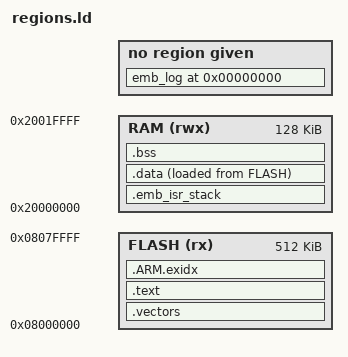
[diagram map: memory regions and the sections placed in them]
/* SPDX-License-Identifier: Apache-2.0 */
/*
 * This file is part of EmbLinkRTOS, a deterministic real-time kernel for microcontrollers.
 * Licensed under the Apache License, Version 2.0; see the LICENSE file at the repository root.
 */

/**
 * @file    regions.ld
 * @brief   Linker script for nucleo_f446ze (STM32F446ZE): the app partition in FLASH, RAM from
 *          sram1 + sram2. The kernel's registration tables are bracketed by name (SPEC-001 §6.4,
 *          HW-006).
 *
 * @details
 * Generated by emb-hwgen 0.1.0, schema v0. Do not edit: change the
 * description and run
 *   hw/gen/emb-hwgen.py generate --system examples/controller/system.yaml
 * (HW-003).
 * Inputs (SHA-256):
 *   arch/cortex_m/arch.yaml
 *     c5c8e451c09717dee1713d07f8311b6d507e3b4c66c42d93e0ce11da6ec76d6d
 *   boards/st/nucleo_f446ze/board.yaml
 *     1525ea206692663af174039e30776d6a9a9b30275c9e5c9bdabf14ac0b70aa19
 *   drivers/bindings.yaml
 *     8ebddec3b88fbfaa96769bf53f915ef6e916352d5abf4b9f676210fcb918d2c9
 *   examples/controller/controller.conf
 *     f7354e5137f5ea50fbd1d5829ff4f5eb88a044100d871d6a8fd7d976339a75f1
 *   examples/controller/system.yaml
 *     2a91f71f1de638aa1ffaa18f0f76fc3ccde44d2560aef98a9a48120775773af3
 *   soc/st/stm32f4/stm32f4.yaml
 *     796886c294250aa81151a620d80d0e43b5ee8e1bf53a07d1d7e2c62e95214dbd
 *   soc/st/stm32f4/stm32f446.yaml
 *     bc475c4bf8703f3bc028f963f6ddf5f1ca508dc726629ea28cca8b38679318f9
 *   soc/st/stm32f4/stm32f446ze.yaml
 *     dabae95e9e4bc984c1a33275966665e0252068e929fe3b430d06589da6bdb6c9
 */
ENTRY(embn_cm_reset)

MEMORY
{
  FLASH (rx)  : ORIGIN = 0x08000000, LENGTH = 512K
  RAM   (rwx) : ORIGIN = 0x20000000, LENGTH = 128K
}

SECTIONS
{
  /* the vector table, then any block the SoC's boot ROM looks for near the image's start
     (the RP2350's IMAGE_DEF, A79) */
  .vectors : { KEEP(*(.vectors)) KEEP(*(.emb_boot_block)) } > FLASH

  .text : {
    *(.text .text.*)
    *(.rodata .rodata.*)
    . = ALIGN(16); /* the table entries' own alignment (sizeof(void *) * 4) */
    __start_emb_init_table = .;
    KEEP(*(emb_init_table))
    __stop_emb_init_table = .;
    . = ALIGN(16);
    __start_emb_test_table = .;
    KEEP(*(emb_test_table))
    __stop_emb_test_table = .;
    . = ALIGN(8);
  } > FLASH

  .ARM.exidx : { *(.ARM.exidx* .gnu.linkonce.armexidx.*) } > FLASH

  /* the interrupt stack, MSP (CONFIG_EMB_ISR_STACK_SIZE, A90): first in RAM, so that an
     overflow runs off the bottom of RAM into a bus fault, not into .data */
  .emb_isr_stack (NOLOAD) : ALIGN(8) {
    __emb_isr_stack_start = .;
    KEEP(*(.emb_isr_stack))
    __emb_isr_stack_end = .;
  } > RAM

  __data_load = LOADADDR(.data);
  .data : ALIGN(8) {
    __data_start = .;
    /* code that runs from RAM, copied with the data: the RP2350's flash routines, which run
       while XIP is off (SPEC-017 §9) */
    *(.ramfunc .ramfunc.*)
    *(.data .data.*)
    . = ALIGN(8);
    __data_end = .;
  } > RAM AT > FLASH

  .bss (NOLOAD) : ALIGN(8) {
    __bss_start = .;
    *(.bss .bss.* COMMON)
    . = ALIGN(8);
    __bss_end = .;
  } > RAM

  end = .;
  /* the crash record's memory (SPEC-015 §4, A73): above the stack and outside every loaded
     segment, so neither startup nor a loader's reset clears it */
  __emb_retained_end = ORIGIN(RAM) + LENGTH(RAM);
  __emb_retained_start = __emb_retained_end - 192;
  /* below it, 32 bytes the test framework keeps across the resets of its fault checks (A89) */
  __emb_test_retained_end = __emb_retained_start;
  __emb_test_retained_start = __emb_test_retained_end - 32;
  __stack_top = __emb_isr_stack_end;
  ASSERT(end <= __emb_test_retained_start, "RAM overflow: .data and .bss reach the retained memory")

  /* the log's call sites (A127): kept in the ELF for tools/logdec and out of the image. At
     address 0, from which a record's identifier is its metadata's offset plus 8; the first 8
     bytes stay empty, so no metadata is at address 0, the null pointer. Last, since setting
     its address moves the location counter. */
  emb_log 0 (INFO) : {
    __start_emb_log = .;
    . += 8;
    KEEP(*(emb_log))
    __stop_emb_log = .;
  }
}
